# R7FA8M1AH register map
Vendor: Renesas; Series: RA8; File version: 1.2
CPU: CM85 r0p0, little endian, MPU, FPU, VTOR, 4 interrupt priority bits
Registers are 32-bit, read-write, reset 0x0 unless marked. A register's access mark holds for its fields unless they carry their own. Offsets are from the block's base; [hi:lo] are bit positions; {n}, {i} and the like mark numbered series; 'fields as' and 'values as' point back to an identical list.

## RMPU — Renesas Memory Protection Unit
Base 0x40000000
Same registers: RMPU_NS 0x50000000
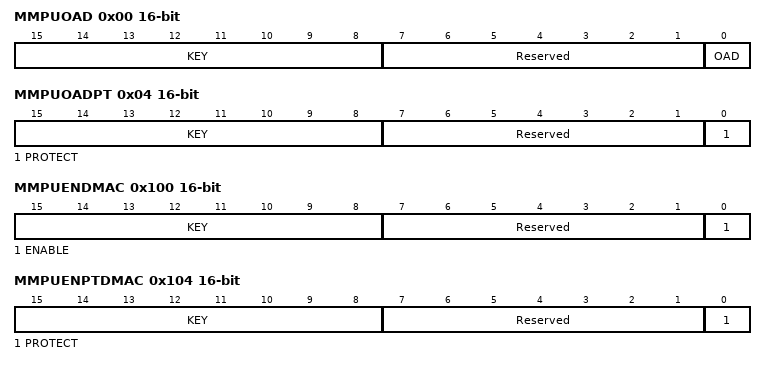
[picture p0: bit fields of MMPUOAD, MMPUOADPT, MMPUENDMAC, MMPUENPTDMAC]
0x00 MMPUOAD 16-bit — MMPU Operation After Detection Register
  [15:8] KEY wo — Key Code
  [7:1] Reserved — These bits are read as 0000000. The write value should be 0000000.
  [0] OAD — Operation after detection
    0=NMI; 1=Reset
0x04 MMPUOADPT 16-bit — MMPU Operation After Detection Protect Register
  [15:8] KEY wo — Key code
  [7:1] Reserved — These bits are read as 0000000. The write value should be 0000000.
  [0] PROTECT — Protection of register
    0=MMPUOAD register writing is possible; 1=MMPUOAD register writing is protected. Read is possible.
0x100 MMPUENDMAC 16-bit — MMPU Enable Register for DMAC
  [15:8] KEY wo — Key Code
  [7:1] Reserved — These bits are read as 0000000. The write value should be 0000000.
  [0] ENABLE — Bus master MPU of DMAC Enable
    0=Bus master MPU of DMAC is disabled; 1=Bus master MPU of DMAC is enabled
0x104 MMPUENPTDMAC 16-bit — MMPU Enable Protect Register for DMAC
  [15:8] KEY wo — Key Code
  [7:1] Reserved — These bits are read as 0000000. The write value should be 0000000.
  [0] PROTECT — Protection of register
    0=MMPUENDMAC register write is possible; 1=MMPUENDMAC register write is protected. Read is possible.
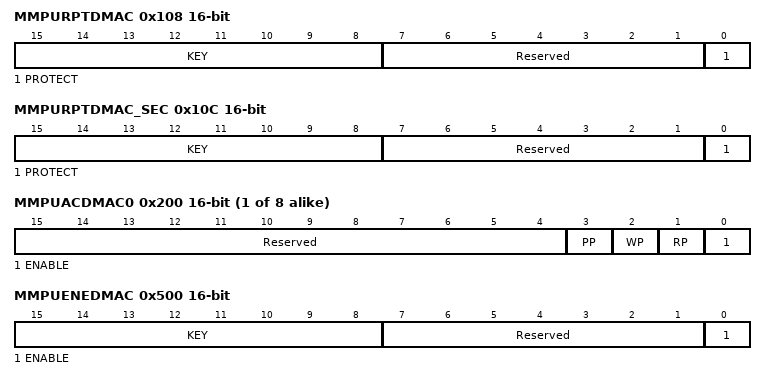
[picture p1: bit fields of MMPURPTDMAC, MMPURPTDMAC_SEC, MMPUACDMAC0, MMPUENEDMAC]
0x108 MMPURPTDMAC 16-bit — MMPU Regions Protect Register for DMAC
  [15:8] KEY wo — Key Code
  [7:1] Reserved — These bits are read as 0000000. The write value should be 0000000.
  [0] PROTECT — Protection of register
    0=Bus master MPU register for DMAC write is possible; 1=Bus master MPU register for DMAC write is protected. Read is possible.
0x10C MMPURPTDMAC_SEC 16-bit — MMPU Regions Protect register for DMAC Secure
  [15:8] KEY wo — Key Code
  [7:1] Reserved — These bits are read as 0000000. The write value should be 0000000.
  [0] PROTECT — Protection of register
    0=Bus master MPU register for DMAC Secure write is possible; 1=Bus master MPU register for DMAC Secure write is protected. Read is possible.
{0x200+0x10*i} MMPUACDMAC{i} (i=0..7) 16-bit — MMPU Access Control Register for DMAC {i}
  [15:4] Reserved — These bits are read as 000000000000. The write value should be 000000000000.
  [3] PP — Privilege protection
    0=Unprivileged access permission; 1=Unprivileged access protection
  [2] WP — Write protection
    0=Write permission; 1=Write protection
  [1] RP — Read protection
    0=Read permission; 1=Read protection
  [0] ENABLE — Region Enable
    0=DMAC region n unit is disabled; 1=DMAC region n unit is enabled
{0x204+0x10*i} MMPUSDMAC{i} (i=0..7) (reset mask 0x1F) — MMPU Start Address Register for DMAC {i}
  [31:0] MMPUS — Region Stat Address : Address where the region starts, for use in region determination.NOTE: The low-order 5 bits are fixed to 0.
{0x208+0x10*i} MMPUEDMAC{i} (i=0..7) reset 0x1F (reset mask 0x1F) — MMPU End Address Register for DMAC {i}
  [31:0] MMPUE — Region End Address : Address where the region end, for use in region determination.NOTE: The low-order 5 bits are fixed to 1.
0x500 MMPUENEDMAC 16-bit — MMPU Enable Register for EDMAC
  [15:8] KEY wo — Key Code
  [7:1] Reserved — These bits are read as 0000000. The write value should be 0000000.
  [0] ENABLE — Bus master MPU of EDMAC Enable
    0=Bus master MPU of EDMAC is disabled; 1=Bus master MPU of EDMAC is enabled
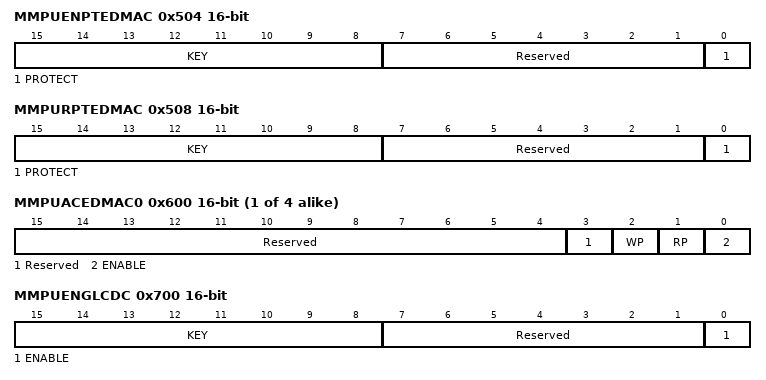
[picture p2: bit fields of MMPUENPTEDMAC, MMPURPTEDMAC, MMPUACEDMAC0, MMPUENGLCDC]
0x504 MMPUENPTEDMAC 16-bit — MMPU Enable Protect Register for EDMAC
  [15:8] KEY wo — Key Code
  [7:1] Reserved — These bits are read as 0000000. The write value should be 0000000.
  [0] PROTECT — Protection of register
    0=MMPUENEDMAC register write is possible; 1=MMPUENEDMAC register write is protected. Read is possible.
0x508 MMPURPTEDMAC 16-bit — MMPU Regions Protect Register for EDMAC
  [15:8] KEY wo — Key Code
  [7:1] Reserved — These bits are read as 0000000. The write value should be 0000000.
  [0] PROTECT — Protection of register
    0=Bus master MPU register for EDMAC write is possible; 1=Bus master MPU register for EDMAC write is protected. Read is possible.
{0x600+0x10*i} MMPUACEDMAC{i} (i=0..3) 16-bit — MMPU Access Control Register for EDMAC {i}
  [15:4] Reserved — These bits are read as 000000000000. The write value should be 000000000000.
  [3] Reserved — This bit is read as 0. The write value should be 0.
  [2] WP — Write protection
    0=Write permission; 1=Write protection
  [1] RP — Read protection
    0=Read permission; 1=Read protection
  [0] ENABLE — Region Enable
    0=EDMAC region n unit is disabled; 1=EDMAC region n unit is enabled
{0x604+0x10*i} MMPUSEDMAC{i} (i=0..3) (reset mask 0x1F) — MMPU Start Address Register for EDMAC {i}
  fields as MMPUSDMAC0
{0x608+0x10*i} MMPUEEDMAC{i} (i=0..3) reset 0x1F (reset mask 0x1F) — MMPU End Address Register for EDMAC {i}
  fields as MMPUEDMAC0
0x700 MMPUENGLCDC 16-bit — MMPU Enable Register for GLCDC
  [15:8] KEY wo — Key Code
  [7:1] Reserved — These bits are read as 0000000. The write value should be 0000000.
  [0] ENABLE — Bus master MPU of GLCDC Enable
    0=Bus master MPU of GLCDC is disabled; 1=Bus master MPU of GLCDC is enabled
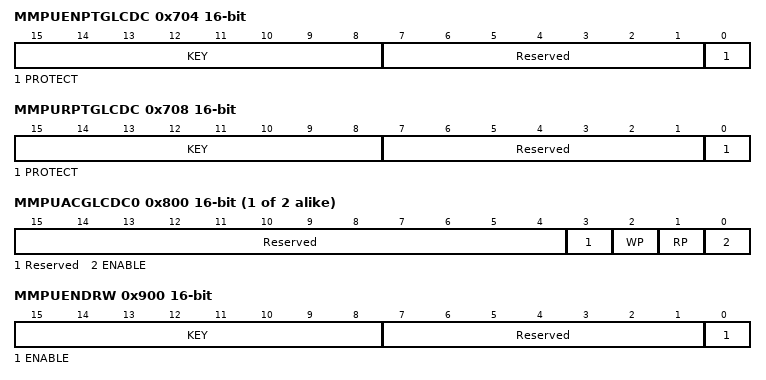
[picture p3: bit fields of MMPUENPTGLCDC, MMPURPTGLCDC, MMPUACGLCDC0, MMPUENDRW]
0x704 MMPUENPTGLCDC 16-bit — MMPU Enable Protect Register for GLCDC
  [15:8] KEY wo — Key Code
  [7:1] Reserved — These bits are read as 0000000. The write value should be 0000000.
  [0] PROTECT — Protection of register
    0=MMPUENGLCDC register write is possible; 1=MMPUENGLCDC register write is protected. Read is possible.
0x708 MMPURPTGLCDC 16-bit — MMPU Regions Protect Register for GLCDC
  [15:8] KEY wo — Key Code
  [7:1] Reserved — These bits are read as 0000000. The write value should be 0000000.
  [0] PROTECT — Protection of register
    0=Bus master MPU register for GLCDC write is possible; 1=Bus master MPU register for GLCDC write is protected. Read is possible.
{0x800+0x10*i} MMPUACGLCDC{i} (i=0..1) 16-bit — MMPU Access Control Register for GLCDC {i}
  [15:4] Reserved — These bits are read as 000000000000. The write value should be 000000000000.
  [3] Reserved — This bit is read as 0. The write value should be 0.
  [2] WP — Write protection
    0=Write permission; 1=Write protection
  [1] RP — Read protection
    0=Read permission; 1=Read protection
  [0] ENABLE — Region Enable
    0=GLCDC region n unit is disabled; 1=GLCDC region n unit is enabled
{0x804+0x10*i} MMPUSGLCDC{i} (i=0..1) (reset mask 0x3FF) — MMPU Start Address Register for GLCDC {i}
  [31:0] MMPUS — Region Stat Address : Address where the region starts, for use in region determination.NOTE: The low-order 10 bits are fixed to 0.
{0x808+0x10*i} MMPUEGLCDC{i} (i=0..1) reset 0x3FF (reset mask 0x3FF) — Graphics Region {i} End Address Register
  [31:0] MMPUE — Region End Address : Address where the region end, for use in region determination.NOTE: The low-order 10 bits are fixed to 1.
0x900 MMPUENDRW 16-bit — MMPU Enable Register for DRW
  [15:8] KEY wo — Key Code
  [7:1] Reserved — These bits are read as 0000000. The write value should be 0000000.
  [0] ENABLE — Bus master MPU of DRW Enable
    0=Bus master MPU of DRW is disabled; 1=Bus master MPU of DRW is enabled
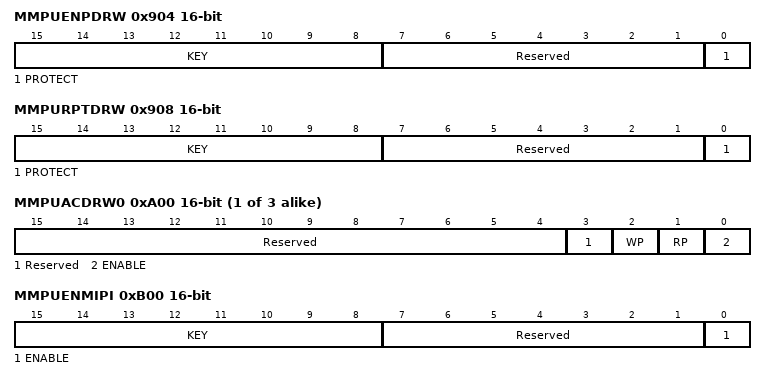
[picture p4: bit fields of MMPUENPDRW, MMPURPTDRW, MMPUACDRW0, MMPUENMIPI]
0x904 MMPUENPDRW 16-bit — MMPU Enable Protect Register for DRW
  [15:8] KEY wo — Key Code
  [7:1] Reserved — These bits are read as 0000000. The write value should be 0000000.
  [0] PROTECT — Protection of register
    0=MMPUENDRW register write is possible; 1=MMPUENDRW register write is protected. Read is possible.
0x908 MMPURPTDRW 16-bit — MMPU Regions Protect Register for DRW
  [15:8] KEY wo — Key Code
  [7:1] Reserved — These bits are read as 0000000. The write value should be 0000000.
  [0] PROTECT — Protection of register
    0=Bus master MPU register for DRW write is possible; 1=Bus master MPU register for DRW write is protected. Read is possible.
{0xA00+0x10*i} MMPUACDRW{i} (i=0..2) 16-bit — MMPU Access Control Register for DRW {i}
  [15:4] Reserved — These bits are read as 000000000000. The write value should be 000000000000.
  [3] Reserved — This bit is read as 0. The write value should be 0.
  [2] WP — Write protection
    0=Write permission; 1=Write protection
  [1] RP — Read protection
    0=Read permission; 1=Read protection
  [0] ENABLE — Region Enable
    0=DRW region n unit is disabled; 1=DRW region n unit is enabled
{0xA04+0x10*i} MMPUSDRW{i} (i=0..2) (reset mask 0x3FF) — MMPU Start Address Register for DRW {i}
  fields as MMPUSGLCDC0
{0xA08+0x10*i} MMPUEDRW{i} (i=0..1) reset 0x3FF (reset mask 0x3FF) — Graphics Region {i} End Address Register
  fields as MMPUEGLCDC0
0xB00 MMPUENMIPI 16-bit — MMPU Enable Register for MIPI
  [15:8] KEY wo — Key Code
  [7:1] Reserved — These bits are read as 0000000. The write value should be 0000000.
  [0] ENABLE — Bus master MPU of MIPI Enable
    0=Bus master MPU of MIPI is disabled; 1=Bus master MPU of MIPI is enabled
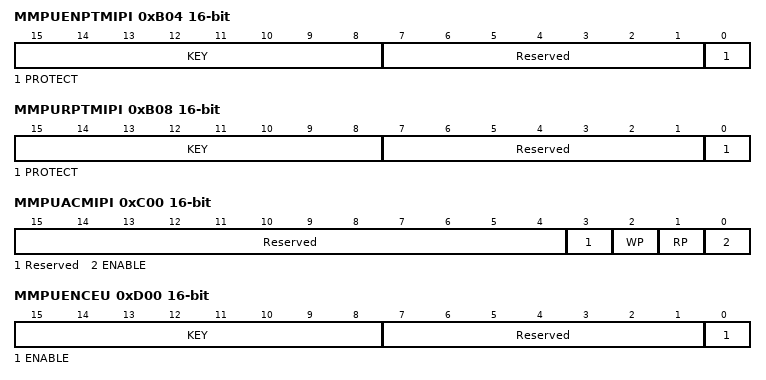
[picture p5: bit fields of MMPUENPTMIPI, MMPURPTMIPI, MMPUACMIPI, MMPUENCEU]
0xB04 MMPUENPTMIPI 16-bit — MMPU Enable Protect Register for MIPI
  [15:8] KEY wo — Key Code
  [7:1] Reserved — These bits are read as 0000000. The write value should be 0000000.
  [0] PROTECT — Protection of register
    0=MMPUENMIPI register write is possible; 1=MMPUENMIPI register write is protected. Read is possible.
0xB08 MMPURPTMIPI 16-bit — MMPU Regions Protect Register for MIPI
  [15:8] KEY wo — Key Code
  [7:1] Reserved — These bits are read as 0000000. The write value should be 0000000.
  [0] PROTECT — Protection of register
    0=Bus master MPU register for MIPI write is possible; 1=Bus master MPU register for MIPI write is protected. Read is possible.
0xC00 MMPUACMIPI 16-bit — MMPU Access Control Register for MIPI
  [15:4] Reserved — These bits are read as 000000000000. The write value should be 000000000000.
  [3] Reserved — This bit is read as 0. The write value should be 0.
  [2] WP — Write protection
    0=Write permission; 1=Write protection
  [1] RP — Read protection
    0=Read permission; 1=Read protection
  [0] ENABLE — Region Enable
    0=MIPI region n unit is disabled; 1=MIPI region n unit is enabled
0xC04 MMPUSMIPI (reset mask 0xFFF) — MMPU Start Address Register for MIPI
  [31:0] MMPUS — Region Stat Address : Address where the region starts, for use in region determination.NOTE: The low-order 12 bits are fixed to 0.
0xC08 MMPUEMIPI reset 0x3FF (reset mask 0x3FF) — MMPU End Address Register for MIPI
  [31:0] MMPUE — Region End Address : Address where the region end, for use in region determination.NOTE: The low-order 12 bits are fixed to 1.
0xD00 MMPUENCEU 16-bit — MMPU Enable Register for CEU
  [15:8] KEY wo — Key Code
  [7:1] Reserved — These bits are read as 0000000. The write value should be 0000000.
  [0] ENABLE — Bus master MPU of CEU Enable
    0=Bus master MPU of CEU is disabled; 1=Bus master MPU of CEU is enabled
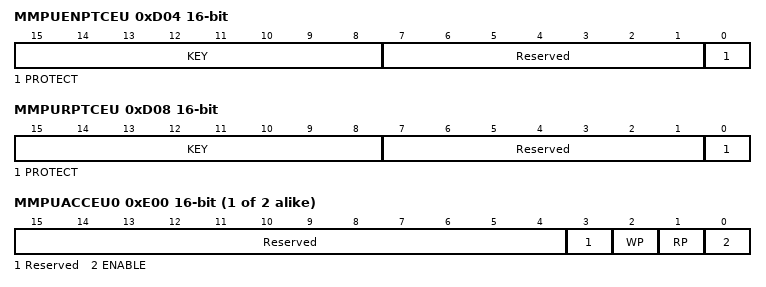
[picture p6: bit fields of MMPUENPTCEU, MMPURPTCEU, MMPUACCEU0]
0xD04 MMPUENPTCEU 16-bit — MMPU Enable Protect Register for CEU
  [15:8] KEY wo — Key Code
  [7:1] Reserved — These bits are read as 0000000. The write value should be 0000000.
  [0] PROTECT — Protection of register
    0=MMPUENCEU register write is possible; 1=MMPUENCEU register write is protected. Read is possible.
0xD08 MMPURPTCEU 16-bit — MMPU Regions Protect Register for CEU
  [15:8] KEY wo — Key Code
  [7:1] Reserved — These bits are read as 0000000. The write value should be 0000000.
  [0] PROTECT — Protection of register
    0=Bus master MPU register for CEU write is possible; 1=Bus master MPU register for CEU write is protected. Read is possible.
{0xE00+0x10*i} MMPUACCEU{i} (i=0..1) 16-bit — MMPU Access Control Register for CEU {i}
  [15:4] Reserved — These bits are read as 000000000000. The write value should be 000000000000.
  [3] Reserved — This bit is read as 0. The write value should be 0.
  [2] WP — Write protection
    0=Write permission; 1=Write protection
  [1] RP — Read protection
    0=Read permission; 1=Read protection
  [0] ENABLE — Region Enable
    0=CEU region n unit is disabled; 1=CEU region n unit is enabled
{0xE04+0x10*i} MMPUSCEU{i} (i=0..1) (reset mask 0xFFF) — MMPU Start Address Register for CEU {i}
  fields as MMPUSMIPI
{0xE08+0x10*i} MMPUECEU{i} (i=0..1) reset 0x3FF (reset mask 0x3FF) — MMPU End Address Register for CEU {i}
  fields as MMPUEMIPI
